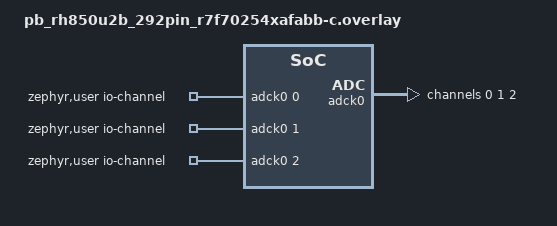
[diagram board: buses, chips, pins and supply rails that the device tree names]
/*
 * Copyright (c) 2026 Renesas Electronics Corporation
 *
 * SPDX-License-Identifier: Apache-2.0
 */

#include <zephyr/dt-bindings/adc/adc.h>

/ {
	zephyr,user {
		io-channels = <&adck0 0>, <&adck0 1>, <&adck0 2>;
	};
};

&adck0 {
	status = "okay";
	vref-mv = <5000>;
	channel-available-mask = <0x07>;

	renesas,scan-group = <0>;
	renesas,start-virtual-channel = <0>;
	renesas,end-virtual-channel = <2>;
	renesas,data-format = "12-bit-unsigned-right-justified";
	renesas,trigger-method = "software";

	channel@0 {
		reg = <0>;
		zephyr,gain = "ADC_GAIN_1";
		zephyr,reference = "ADC_REF_VDD_1";
		zephyr,acquisition-time = <ADC_ACQ_TIME_DEFAULT>;
		zephyr,resolution = <12>;
		zephyr,vref-mv = <5000>;

		renesas,virtual-channel = <0>;
		renesas,physical-channel = <4>; /* AN010 */
		renesas,conversion-type = "normal";
	};

	channel@1 {
		reg = <1>;
		zephyr,gain = "ADC_GAIN_1";
		zephyr,reference = "ADC_REF_VDD_1";
		zephyr,acquisition-time = <ADC_ACQ_TIME_DEFAULT>;
		zephyr,resolution = <12>;
		zephyr,vref-mv = <5000>;

		renesas,virtual-channel = <1>;
		renesas,physical-channel = <5>;
		renesas,conversion-type = "normal";
	};

	channel@2 {
		reg = <2>;
		zephyr,gain = "ADC_GAIN_1";
		zephyr,reference = "ADC_REF_VDD_1";
		zephyr,acquisition-time = <ADC_ACQ_TIME_DEFAULT>;
		zephyr,resolution = <12>;
		zephyr,vref-mv = <5000>;

		renesas,virtual-channel = <2>;
		renesas,physical-channel = <6>;
		renesas,conversion-type = "normal";
	};
};
